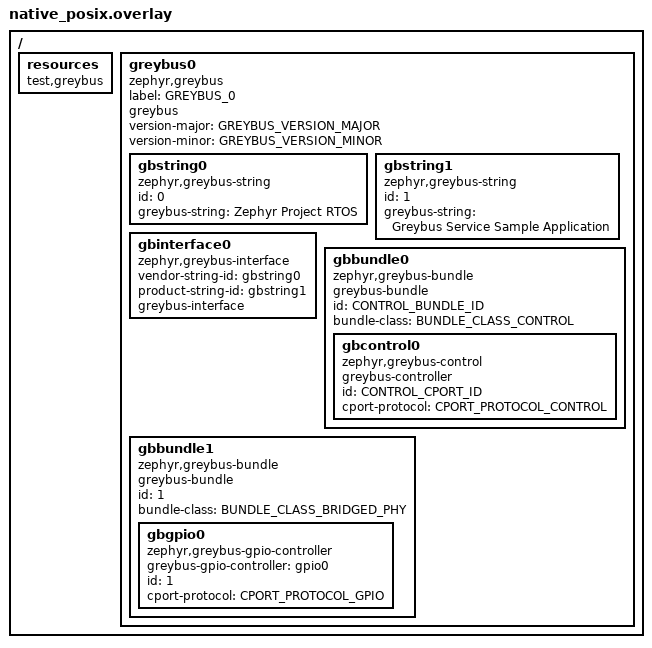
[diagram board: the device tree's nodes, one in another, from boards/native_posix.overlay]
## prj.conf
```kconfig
CONFIG_ZTEST=y

#CONFIG_REQUIRES_FULL_LIBC=y
#CONFIG_NEWLIB_LIBC=y
CONFIG_GPIO=y
CONFIG_GREYBUS=y
#CONFIG_GB_LOG_LEVEL=4
#CONFIG_GREYBUS_AUDIO=y
#CONFIG_GREYBUS_CAMERA=y
CONFIG_GREYBUS_CONTROL=y
CONFIG_GREYBUS_GPIO=y
#CONFIG_GREYBUS_DEBUG=y
#CONFIG_GREYBUS_HID=y
#CONFIG_GREYBUS_I2C=y
#CONFIG_GREYBUS_LIGHTS=y
#CONFIG_GREYBUS_LOOPBACK=y
#CONFIG_GREYBUS_POWER_SUPPLY=y
#CONFIG_GREYBUS_PWM=y
#CONFIG_GREYBUS_SDIO=y
#CONFIG_GREYBUS_SPI=y
#CONFIG_GREYBUS_UART=y
#CONFIG_GREYBUS_USB=y
#CONFIG_GREYBUS_VIBRATOR=y
CONFIG_CONSOLE_SUBSYS=y
#CONFIG_CONSOLE_GETCHAR=y
CONFIG_NO_OPTIMIZATIONS=y
CONFIG_MINIMAL_LIBC_MALLOC_ARENA_SIZE=16384
#CONFIG_MINIMAL_LIBC_MALLOC_ARENA_SIZE=32768
CONFIG_GREYBUS_STATIC_MANIFEST=y
# Generic networking options
CONFIG_NETWORKING=y
CONFIG_NET_UDP=y
CONFIG_NET_TCP=y
CONFIG_NET_IPV6=y
CONFIG_NET_IPV4=y
CONFIG_NET_SOCKETS=y
CONFIG_NET_SOCKETS_POSIX_NAMES=y
CONFIG_POSIX_MAX_FDS=32

# Kernel options
CONFIG_MAIN_STACK_SIZE=1024
#CONFIG_ENTROPY_GENERATOR=y
CONFIG_TEST_RANDOM_GENERATOR=y
CONFIG_INIT_STACKS=y

# Logging
CONFIG_NET_LOG=y
CONFIG_LOG=y
CONFIG_NET_STATISTICS=y
CONFIG_PRINTK=y

# Network buffers
CONFIG_NET_PKT_RX_COUNT=4
CONFIG_NET_PKT_TX_COUNT=4
CONFIG_NET_BUF_RX_COUNT=16
CONFIG_NET_BUF_TX_COUNT=16
CONFIG_NET_CONTEXT_NET_PKT_POOL=y

# IP address options
CONFIG_NET_IF_UNICAST_IPV6_ADDR_COUNT=3
CONFIG_NET_IF_MCAST_IPV6_ADDR_COUNT=4
CONFIG_NET_MAX_CONTEXTS=10

# Network shell
CONFIG_NET_SHELL=y
CONFIG_SHELL=y

# Network application options and configuration
CONFIG_NET_CONFIG_SETTINGS=y
CONFIG_NET_CONFIG_MY_IPV6_ADDR="2001:db8::1"
CONFIG_NET_CONFIG_PEER_IPV6_ADDR="2001:db8::2"
CONFIG_NET_CONFIG_MY_IPV4_ADDR="192.0.2.1"
CONFIG_NET_CONFIG_PEER_IPV4_ADDR="192.0.2.2"

# How many client can connect to echo-server simultaneously
#CONFIG_NET_SAMPLE_NUM_HANDLERS=1
```

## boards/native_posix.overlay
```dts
/*
 * Copyright (c) 2020 Friedt Professional Engineering Services, Inc
 *
 * SPDX-License-Identifier: Apache-2.0
 */
 #include <dt-bindings/greybus/greybus.h>

/ {
	resources {
		compatible = "test,greybus";
	};

	greybus0: greybus0 {
		compatible = "zephyr,greybus";
		label = "GREYBUS_0";
		greybus;
	};
};

&greybus0 {
	status = "okay";
	/* defaults in effect, so this isn't necessary */
	version-major = <GREYBUS_VERSION_MAJOR>;
	version-minor = <GREYBUS_VERSION_MINOR>;

	gbstring0: gbstring0 {
		status = "okay";
		compatible = "zephyr,greybus-string";
		id = <0>;
		greybus-string = "Zephyr Project RTOS";
	};

	gbstring1: gbstring1 {
		status = "okay";
		compatible = "zephyr,greybus-string";
		id = <1>;
		greybus-string = "Greybus Service Sample Application";
	};

	gbinterface0 {
		status = "okay";
		compatible = "zephyr,greybus-interface";
		vendor-string-id = <&gbstring0>;
		product-string-id = <&gbstring1>;
		greybus-interface;
	};

	gbbundle0 {
		status = "okay";
		compatible = "zephyr,greybus-bundle";
		greybus-bundle;
		/* Control Bundle 0
		 * Note: control bundle 0 and control cport 0 are optional
		 * Since instance numbers automatically begin at 0, the id
		 * is a mandatory field for bundles and cports.
		 */
		id = <CONTROL_BUNDLE_ID>;
		bundle-class = <BUNDLE_CLASS_CONTROL>;

		gbcontrol0 {
			status = "okay";
			compatible = "zephyr,greybus-control";
			greybus-controller;
			/* Control CPort 0
			 * Note: control bundle 0 and control cport 0 are optional
			 * Since instance numbers automatically begin at 0, the id
			 * is a mandatory field for bundles and cports.
			 */
			id = <CONTROL_CPORT_ID>;
			cport-protocol = <CPORT_PROTOCOL_CONTROL>; 
		};
	};
	
	gbbundle1 {
		status = "okay";
		compatible = "zephyr,greybus-bundle";
		greybus-bundle;
		id = <1>;
		bundle-class = <BUNDLE_CLASS_BRIDGED_PHY>;		
				
		gbgpio0 {
			status = "okay";
			compatible = "zephyr,greybus-gpio-controller";
			greybus-gpio-controller = <&gpio0>;
			id = <1>;
			cport-protocol = <CPORT_PROTOCOL_GPIO>;
		};
	};
};
```

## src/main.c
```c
/*
 * Copyright (c) 2020 Friedt Professional Engineering Services, Inc
 *
 * SPDX-License-Identifier: Apache-2.0
 */

#include <device.h>
#include <zephyr.h>

#define LOG_LEVEL 11
#include <logging/log.h>
LOG_MODULE_REGISTER(greybus_test);

void test_main(void) {
	LOG_INF("%s(): ahoy!", __func__);
    for(;;) {
    	k_sleep(K_MSEC(500));
    }
}
```

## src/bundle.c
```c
#include <stdint.h>
#include <zephyr.h>
#include <greybus/manifecto/manifest.h>

#define DT_DRV_COMPAT zephyr_greybus_bundle
#include <device.h>
#include <devicetree.h>

#define LOG_LEVEL 11
#include <logging/log.h>
LOG_MODULE_REGISTER(greybus_test_bundle);

#include <greybus/platform.h>

struct greybus_bundle_config {
    const uint8_t id;
    const BundleClass class_;
    const char *const bus_name;
};

static int greybus_bundle_init(struct device *dev) {

	const struct greybus_bundle_config *const config =
			(const struct greybus_bundle_config *)dev->config_info;

	int r;
	struct greybus_platform_api *api;
	struct device *bus;

	bus = device_get_binding(config->bus_name);
	if (NULL == bus) {
		LOG_ERR("greybus bundle: failed to get binding for device '%s'", config->bus_name);
		return -ENODEV;
	}

	api = (struct greybus_platform_api *)bus->driver_api;
	if (NULL == api) {
		LOG_ERR("greybus bundle: failed to get driver_api for device '%s'", config->bus_name);
		return -EINVAL;
	}

	r = api->add_bundle(bus, config->id, config->class_);
	if (r < 0) {
		LOG_ERR("greybus bundle: add_bundle() failed: %d", r);
		return r;
	}

	LOG_INF("probed greybus bundle %u: class: %u", config->id, config->class_);

    return 0;
}

extern int gb_service_defer_init(struct device *, int (*init)(struct device *));
static int defer_greybus_bundle_init(struct device *dev) {
	return gb_service_defer_init(dev, &greybus_bundle_init);
}

#define DEFINE_GREYBUS_BUNDLE(_num)                                     \
																		\
        static const struct greybus_bundle_config 						\
			greybus_bundle_config_##_num = {      						\
				.id = DT_INST_PROP(_num, id),							\
				.class_ = DT_INST_PROP(_num, bundle_class),				\
				.bus_name = 											\
					DT_LABEL(DT_PARENT(DT_DRV_INST(_num))),				\
        };                                                              \
                                                                        \
        DEVICE_INIT(greybus_bundle_##_num, "GBBUNDLE_" #_num,			\
                            defer_greybus_bundle_init,						\
							NULL,										\
                            &greybus_bundle_config_##_num,				\
							POST_KERNEL,								\
                            CONFIG_KERNEL_INIT_PRIORITY_DEVICE);

DT_INST_FOREACH_STATUS_OKAY(DEFINE_GREYBUS_BUNDLE);
```

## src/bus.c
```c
#include <stdint.h>
#include <zephyr.h>
#include <greybus/manifecto/manifest.h>

#define DT_DRV_COMPAT zephyr_greybus
#include <device.h>

#define LOG_LEVEL 11
#include <logging/log.h>
LOG_MODULE_REGISTER(greybus_test_bus);

struct greybus_config {
    const uint8_t id;
};

struct greybus_data {
	manifest_t manifest;
};

static int greybus_init(struct device *dev) {

	const struct greybus_config *const config =
			(const struct greybus_config *)dev->config_info;
	struct greybus_data *const data =
			(struct greybus_data *)dev->driver_data;

	data->manifest = manifest_new();
	if (NULL == data->manifest) {
		LOG_ERR("manifest_new() failed");
		return -ENOMEM;
	}

	LOG_INF("probed bus %u", config->id);

    return 0;
}

#define DEFINE_GREYBUS(_num)                                     	\
																	\
        static const struct greybus_config 							\
			greybus_config_##_num = {      							\
				.id = _num,                                 		\
        };															\
        															\
		static struct greybus_data greybus_data_##_num;				\
																	\
        DEVICE_INIT(greybus_##_num, "GREYBUS_" #_num,				\
                            greybus_init, &greybus_data_##_num,		\
                            &greybus_config_##_num, POST_KERNEL,	\
                            CONFIG_KERNEL_INIT_PRIORITY_DEVICE);

DT_INST_FOREACH_STATUS_OKAY(DEFINE_GREYBUS);
```

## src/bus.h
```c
#ifndef ASDFGHJ_
#define ASDFGHJ_

#include <stdint.h>
#include <device.h>
#include <greybus/manifecto/manifest.h>

/*
 * Should probably be in greybus/platform.h
 *
 * Used for drivers to add their descriptors to the Greybus Manifest
 * Intermediate Represetntation (IR), extract sufficient information
 * to start the Greybus 
 */

struct bus_api {
	int (*add_interface)(struct device *bus, uint16_t vendor_string_id,
            uint16_t product_string_id);
	int (*add_string)(struct device *bus, uint8_t id, const char *string_);
	int (*add_bundle)(struct device *bus, uint8_t id, BundleClass class_);
	int (*add_cport)(struct device *bus, uint8_t id, BundleClass class_, CPortProtocol protocol);
	int (*num_cports)(struct device *bus);
	int (*gen_mnfb)(struct device *bus, uint8_t **mnfb, size_t *mnfb_size);
	void (*fini)(struct device *bus);
};

#endif /* ASDFGHJ_ */
```

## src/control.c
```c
#include <stdint.h>
#include <zephyr.h>
#include <dt-bindings/greybus/greybus.h>

#define DT_DRV_COMPAT zephyr_greybus_control
#include <device.h>

#define LOG_LEVEL 11
#include <logging/log.h>
LOG_MODULE_REGISTER(greybus_test_control);

#include "bus.h"

struct greybus_control_config {
    const uint8_t id;
    const char *bus_name;
};

static int greybus_control_init(struct device *dev) {

    struct greybus_control_config *config =
        (struct greybus_control_config *)dev->config_info;
    int r;
    struct device *bus;
    struct bus_api *api;

    bus = device_get_binding(config->bus_name);
    if (NULL == bus) {
		LOG_ERR("control: failed to get binding for device '%s'", config->bus_name);
    	return -ENODEV;
    }

    api = (struct bus_api *) bus->driver_api;
    if (NULL == api) {
		LOG_ERR("control: failed to get driver_api for '%s'", config->bus_name);
    	return -EINVAL;
    }

    r = api->add_cport(bus, config->id, BUNDLE_CLASS_CONTROL, CPORT_PROTOCOL_CONTROL);
    if (r < 0) {
		LOG_ERR("control: failed to get driver_api for '%s'", config->bus_name);
		return r;
    }

    LOG_INF("probed cport %u: class: %u protocol: %u", config->id,
		BUNDLE_CLASS_CONTROL, CPORT_PROTOCOL_CONTROL);

    return 0;
}

extern int defer_init(struct device *, int (*init)(struct device *));
static int defer_greybus_control_init(struct device *dev) {
	return defer_init(dev, &greybus_control_init);
}

#define DEFINE_GREYBUS_CONTROL(_num)										\
																			\
		BUILD_ASSERT(DT_PROP(DT_PARENT(DT_DRV_INST(_num)), bundle_class)	\
			== BUNDLE_CLASS_CONTROL, "BUNDLE_CLASS_CONTROL required"); 		\
																			\
		BUILD_ASSERT(DT_PROP(DT_DRV_INST(_num), cport_protocol) 			\
			== CPORT_PROTOCOL_CONTROL, "CPORT_PROTOCOL_CONTROL required"); 	\
																			\
		static const struct greybus_control_config							\
			greybus_control_config_##_num = {								\
                .id = (uint8_t) _num,										\
				.bus_name = 												\
					DT_LABEL(DT_PARENT(DT_PARENT(DT_DRV_INST(_num)))),		\
        };																	\
        																	\
        DEVICE_INIT(gpio_control_##_num, "GBCONTROL_" #_num,				\
                            defer_greybus_control_init,						\
							NULL,											\
                            &greybus_control_config_##_num, POST_KERNEL,	\
                            CONFIG_KERNEL_INIT_PRIORITY_DEVICE);

DT_INST_FOREACH_STATUS_OKAY(DEFINE_GREYBUS_CONTROL);
```

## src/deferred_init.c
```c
#include <errno.h>
#include <stddef.h>
#include <stdint.h>
#include <stdlib.h>

/*
 * FIXME: currently, Zephyr does not guarantee that parent DeviceTree nodes are
 * initialized before child DeviceTree nodes. This has the unfortunate side
 * effect of pushing-off device initialization to the application.
 * It's possible that Zephyr may initialize things in the correct order if
 * phandles are used instead, but that isn't clear at this point.
 *
 * E: greybus bundle: failed to get driver_api for device 'GREYBUS_0'
 * E: greybus bundle: failed to get driver_api for device 'GREYBUS_0'
 * I: probed greybus: 0 major: 0 minor: 1
 * I: probed cport 0: class: 0 protocol: 0
 * I: probed cport 0: class: 10 protocol: 2
 * E: failed to get driver_api for device 'GREYBUS_0'
 * E: greybus string: driver_api was NULL
 * E: greybus string: driver_api was NULL
 * E: Cannot create zeth (-1)
 * *** Booting Zephyr OS build zephyr-v2.3.0-733-g5217cd775382  ***
 * I: Initializing network
 * I: IPv4 address: 192.0.2.1
 * I: test_main(): ahoy!
 * I: IPv6 address: fe80::5eff:fe00:533b
 * I: IPv6 address: fe80::5eff:fe00:533b
 * ^C
 *
 * pabigot is working on a PR to address this, which reorders custom
 * elf-sections at link-time in order to create the proper order.
 *
 * See https://github.com/zephyrproject-rtos/zephyr/pull/26616 for details.
 */

struct definit {
	struct device *dev;
	int (*init)(struct device *);
};
static size_t definits_size;
static struct definit *definits;

int defer_init(struct device *dev, int (*init)(struct device *)) {
	size_t n = definits_size;
	struct definit *tmp;

	tmp = realloc(definits, (n + 1) * sizeof(*tmp));
	if (NULL == tmp) {
		return -ENOMEM;
	}

	definits = tmp;
	definits[n].dev = dev;
	definits[n].init = init;

	definits_size++;

	return 0;
}

int deferred_init(void) {
	int r = 0;
	int rr = 0;
	struct device *dev;
	int (*init)(struct device *);

	for(size_t i = 0; i < definits_size; ++i) {

		dev = definits[i].dev;
		init = definits[i].init;

		r = init(dev);
		if (r < 0) {
			if (0 == rr) {
				rr = r;
			}
		}
	}

	if (NULL != definits) {
		free(definits);
		definits = NULL;
		definits_size = 0;
	}

	return rr;
}
```

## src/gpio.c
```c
#include <stdint.h>
#include <zephyr.h>
#include <dt-bindings/greybus/greybus.h>

#define DT_DRV_COMPAT zephyr_greybus_gpio_controller
#include <device.h>

#define LOG_LEVEL 11
#include <logging/log.h>
LOG_MODULE_REGISTER(greybus_test_gpio_control);

#include "bus.h"

struct greybus_gpio_control_config {
    const uint8_t id;
    const char *const greybus_gpio_controller_name;
    const char *const bus_name;
};

struct greybus_gpio_control_data {
    struct device *greybus_gpio_controller;
};

static int greybus_gpio_control_init(struct device *dev) {

	struct greybus_gpio_control_data *drv_data =
        (struct greybus_gpio_control_data *)dev->driver_data;
    struct greybus_gpio_control_config *config =
        (struct greybus_gpio_control_config *)dev->config_info;
    int r;
    struct device *bus;
    struct bus_api *api;

    drv_data->greybus_gpio_controller =
        device_get_binding(config->greybus_gpio_controller_name);
    if (NULL == drv_data->greybus_gpio_controller) {
		LOG_ERR("gpio control: failed to get binding for device '%s'",
			config->greybus_gpio_controller_name);
		return -ENODEV;
    }

    bus = device_get_binding(config->bus_name);
    if (NULL == bus) {
		LOG_ERR("gpio control: failed to get binding for device '%s'", config->bus_name);
    	return -ENODEV;
    }

    api = (struct bus_api *) bus->driver_api;
    if (NULL == api) {
		LOG_ERR("gpio control: failed to get driver_api for '%s'", config->bus_name);
    	return -EINVAL;
    }

    r = api->add_cport(bus, config->id, BUNDLE_CLASS_BRIDGED_PHY, CPORT_PROTOCOL_GPIO);
    if (r < 0) {
		LOG_ERR("gpio control: failed to get driver_api for '%s'", config->bus_name);
		return r;
    }

    LOG_INF("probed cport %u: class: %u protocol: %u", config->id,
		BUNDLE_CLASS_BRIDGED_PHY, CPORT_PROTOCOL_GPIO);

    return 0;
}

extern int defer_init(struct device *, int (*init)(struct device *));
static int defer_greybus_gpio_control_init(struct device *dev) {
	return defer_init(dev, &greybus_gpio_control_init);
}

#define DEFINE_GREYBUS_GPIO_CONTROL(_num)										\
																				\
		BUILD_ASSERT(DT_PROP(DT_PARENT(DT_DRV_INST(_num)), bundle_class)		\
		== BUNDLE_CLASS_BRIDGED_PHY, "BUNDLE_CLASS_BRIDGED_PHY required"); 		\
																				\
		BUILD_ASSERT(DT_PROP(DT_DRV_INST(_num), cport_protocol) 				\
		== CPORT_PROTOCOL_GPIO, "CPORT_PROTOCOL_GPIO required"); 				\
																				\
		static struct greybus_gpio_control_config								\
			greybus_gpio_control_config_##_num = {								\
                .id = (uint8_t)DT_INST_PROP(_num, id),							\
				.greybus_gpio_controller_name = 								\
                    DT_LABEL(DT_PHANDLE(DT_DRV_INST(_num), 						\
                    		greybus_gpio_controller)), 							\
				.bus_name = 									\
					DT_LABEL(DT_PARENT(DT_PARENT(DT_DRV_INST(_num)))),		\
        };																		\
        																		\
        static struct greybus_gpio_control_data									\
			greybus_gpio_control_data_##_num;									\
        																		\
        DEVICE_INIT(gpio_gpio_control_##_num, "GBGPIO_" #_num,					\
                            defer_greybus_gpio_control_init,					\
							&greybus_gpio_control_data_##_num,					\
                            &greybus_gpio_control_config_##_num, POST_KERNEL,	\
                            CONFIG_KERNEL_INIT_PRIORITY_DEVICE);

DT_INST_FOREACH_STATUS_OKAY(DEFINE_GREYBUS_GPIO_CONTROL);
```

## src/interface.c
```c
#include <errno.h>
#include <stdint.h>
#include <zephyr.h>

#define DT_DRV_COMPAT zephyr_greybus_interface
#include <device.h>
#include <devicetree.h>

#define LOG_LEVEL 11
#include <logging/log.h>
LOG_MODULE_REGISTER(greybus_test_interface);

#include <greybus/platform.h>

struct greybus_interface_config {
	const uint8_t num;
	const uint16_t vendor_string_id;
	const uint16_t product_string_id;
	const char *const bus_name;
};

static int greybus_interface_init(struct device *dev) {

	const struct greybus_interface_config *config =
		(struct greybus_interface_config *)dev->config_info;

	struct device *bus;
	struct greybus_platform_api *api;
	int r;

	bus = device_get_binding(config->bus_name);
	if (NULL == bus) {
		LOG_ERR("failed to get binding for device '%s'", config->bus_name);
		return -ENODEV;
	}

	api = (struct greybus_platform_api *)bus->driver_api;
	if (NULL == api) {
		LOG_ERR("failed to get driver_api for device '%s'", config->bus_name);
		return -EINVAL;
	}

	r = api->add_interface(bus, config->vendor_string_id, config->product_string_id);
	if (r < 0) {
		LOG_ERR("add_interface() failed: %d", r);
		return r;
	}

	LOG_INF("probed greybus interface %u", config->num);

    return 0;
}

extern int gb_service_defer_init(struct device *, int (*init)(struct device *));
static int defer_greybus_interface_init(struct device *dev) {
	return gb_service_defer_init(dev, &greybus_interface_init);
}


#define DEFINE_GREYBUS_INTERFACE(_num)						\
															\
        static const struct greybus_interface_config		\
			greybus_interface_config_##_num = {				\
			.num = (uint8_t) _num,							\
			.vendor_string_id =								\
				DT_PROP(DT_PHANDLE(DT_DRV_INST(_num), 		\
					vendor_string_id), id),					\
			.product_string_id =							\
				DT_PROP(DT_PHANDLE(DT_DRV_INST(_num), 		\
					product_string_id), id),				\
			.bus_name = 									\
				DT_LABEL(DT_PARENT(DT_DRV_INST(_num))),		\
        };													\
        													\
        DEVICE_INIT(greybus_interface_##_num,				\
			"GBINTERFACE_" #_num,							\
			defer_greybus_interface_init,					\
			NULL,											\
			&greybus_interface_config_##_num, POST_KERNEL,	\
			CONFIG_KERNEL_INIT_PRIORITY_DEVICE);

DT_INST_FOREACH_STATUS_OKAY(DEFINE_GREYBUS_INTERFACE);
```

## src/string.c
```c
#include <stdint.h>
#include <zephyr.h>

#define DT_DRV_COMPAT zephyr_greybus_string
#include <device.h>

#define LOG_LEVEL 11
#include <logging/log.h>
LOG_MODULE_REGISTER(greybus_test_string);

#include <greybus/platform.h>

struct greybus_string_config {
    const uint16_t id;
    const char *const string_;
    const char *const bus_name;
};

static int greybus_string_init(struct device *dev) {
	const struct greybus_string_config *config =
			(const struct greybus_string_config *)dev->config_info;

	struct device *bus;
	struct greybus_platform_api *api;
	int r;

	bus = device_get_binding(config->bus_name);
	if (NULL == bus) {
		LOG_ERR("greybus string: device_get_binding() failed for '%s'", config->bus_name);
		return -EAGAIN;
	}

	api = (struct greybus_platform_api *)bus->driver_api;
	if (NULL == api) {
		LOG_ERR("greybus string: driver_api was NULL");
		return -EINVAL;
	}

	r = api->add_string(bus, config->id, config->string_);
	if (r < 0) {
		LOG_ERR("greybus string: add_string() failed: %d", r);
		return r;
	}

	LOG_INF("probed greybus string %u: %s", config->id, config->string_);

    return 0;
}

extern int gb_service_defer_init(struct device *, int (*init)(struct device *));
static int defer_greybus_string_init(struct device *dev) {
	return gb_service_defer_init(dev, &greybus_string_init);
}

#define DEFINE_GREYBUS_STRING(_num)                                     \
																		\
        static const struct greybus_string_config 						\
			greybus_string_config_##_num = {      						\
				.id = (uint16_t)DT_INST_PROP(_num, id),					\
				.string_ = DT_INST_PROP(_num, greybus_string),			\
				.bus_name = 											\
					DT_LABEL(DT_PARENT(DT_DRV_INST(_num))),				\
        };                                                              \
                                                                        \
        DEVICE_INIT(greybus_string_##_num, "GBSTRING_" #_num,			\
        		defer_greybus_string_init, NULL,               	\
                            &greybus_string_config_##_num, POST_KERNEL,	\
                            CONFIG_KERNEL_INIT_PRIORITY_DEVICE);

DT_INST_FOREACH_STATUS_OKAY(DEFINE_GREYBUS_STRING);
```

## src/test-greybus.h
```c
#ifndef TESTS_SUBSYS_TEST_GREYBUS_H_
#define TESTS_SUBSYS_TEST_GREYBUS_H_

#ifdef __cplusplus
extern "C" {
#endif

#if DT_NODE_HAS_STATUS(DT_INST(0, test_greybus_gpio), okay)
/* Execution of the test requires hardware configuration described in
 * devicetree.  See the test,gpio_basic_api binding local to this test
 * for details.
 *
 * If this is not present devices that have gpio-0, gpio-1, or gpio-2
 * aliases are supported for build-only tests.
 */
#define DEV_NAME DT_GPIO_LABEL(DT_INST(0, test_greybus_gpio), out_gpios)
#define PIN_OUT DT_GPIO_PIN(DT_INST(0, test_greybus_gpio, out_gpios)
#define PIN_IN DT_GPIO_PIN(DT_INST(0, test_greybus_gpio), in_gpios)

#elif DT_NODE_HAS_STATUS(DT_ALIAS(gpio_0), okay)
#define DEV_NAME DT_LABEL(DT_ALIAS(gpio_0))
#elif DT_NODE_HAS_STATUS(DT_ALIAS(gpio_1), okay)
#define DEV_NAME DT_LABEL(DT_ALIAS(gpio_1))
#elif DT_NODE_HAS_STATUS(DT_ALIAS(gpio_3), okay)
#define DEV_NAME DT_LABEL(DT_ALIAS(gpio_3))
#else
#error Unsupported board
#endif

#ifndef PIN_OUT
/* For build-only testing use fixed pins. */
#define PIN_OUT 2
#define PIN_IN 3
#endif

#ifdef __cplusplus
}
#endif

#endif /* TESTS_SUBSYS_TEST_GREYBUS_H_ */
```
